# STM32F746ZGY7 register map
File version: 1.0
Registers are 32-bit, access not given, reset 0x0 unless marked. A register's access mark holds for its fields unless they carry their own. Offsets are from the block's base; [hi:lo] are bit positions; {n}, {i} and the like mark numbered series.

## ADC1
Base 0x40012000
Same registers: ADC3 0x40012200
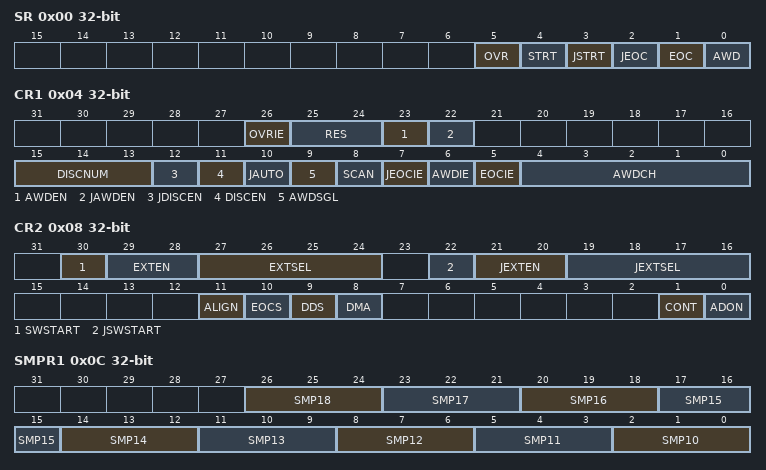
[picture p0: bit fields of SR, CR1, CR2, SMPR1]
0x00 SR
  [5] OVR, [4] STRT, [3] JSTRT, [2] JEOC, [1] EOC, [0] AWD
0x04 CR1
  [26] OVRIE, [25:24] RES, [23] AWDEN, [22] JAWDEN, [15:13] DISCNUM, [12] JDISCEN, [11] DISCEN, [10] JAUTO, [9] AWDSGL, [8] SCAN, [7] JEOCIE, [6] AWDIE, [5] EOCIE, [4:0] AWDCH
0x08 CR2
  [30] SWSTART, [29:28] EXTEN, [27:24] EXTSEL, [22] JSWSTART, [21:20] JEXTEN, [19:16] JEXTSEL, [11] ALIGN, [10] EOCS, [9] DDS, [8] DMA, [1] CONT, [0] ADON
0x0C SMPR1
  [3n-28:3n-30] SMP{n} (n=10..18)
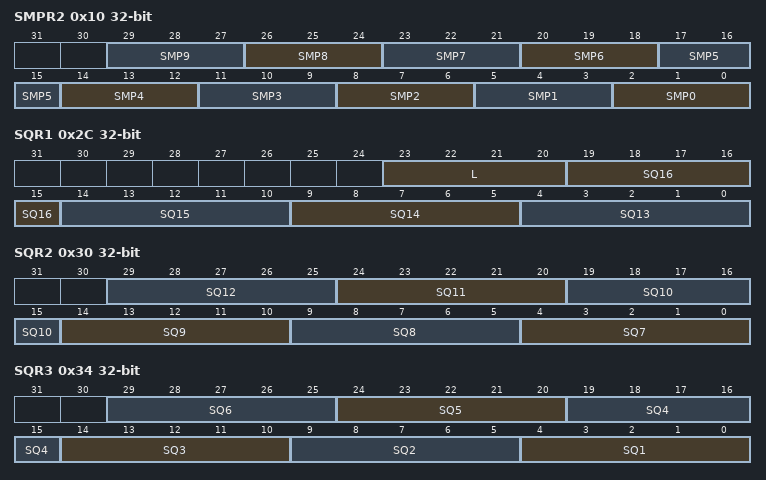
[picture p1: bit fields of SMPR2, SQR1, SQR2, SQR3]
0x10 SMPR2
  [3n+2:3n] SMP{n} (n=0..9)
{0x10+4i} JOFR{i} (i=1..4)
  [11:0] JOFFSET{i}
0x24 HTR
  [11:0] HT
0x28 LTR
  [11:0] LT
0x2C SQR1
  [23:20] L, [5n-61:5n-65] SQ{n} (n=13..16)
0x30 SQR2
  [5n-31:5n-35] SQ{n} (n=7..12)
0x34 SQR3
  [5n-1:5n-5] SQ{n} (n=1..6)
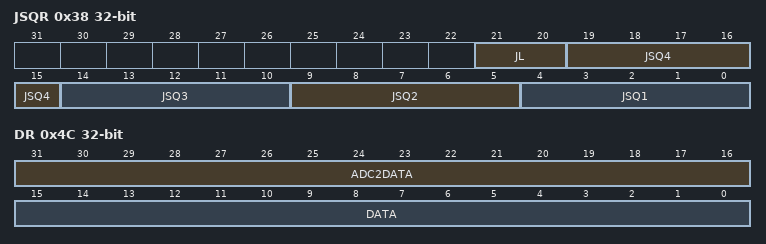
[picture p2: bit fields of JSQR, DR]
0x38 JSQR
  [21:20] JL, [5n-1:5n-5] JSQ{n} (n=1..4)
{0x38+4i} JDR{i} (i=1..4)
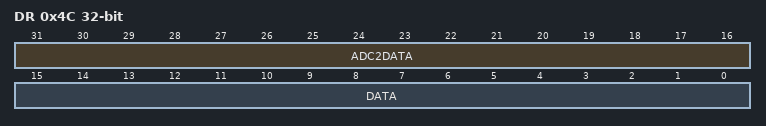
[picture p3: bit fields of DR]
0x4C DR
  [31:16] ADC2DATA, [15:0] DATA

## ADC2
Base 0x40012100
Registers as ADC1; these are added or differ:
0x4C DR
  [31:16] ADC2DATA, [15:0] DATA

## ADC
Base 0x40012300
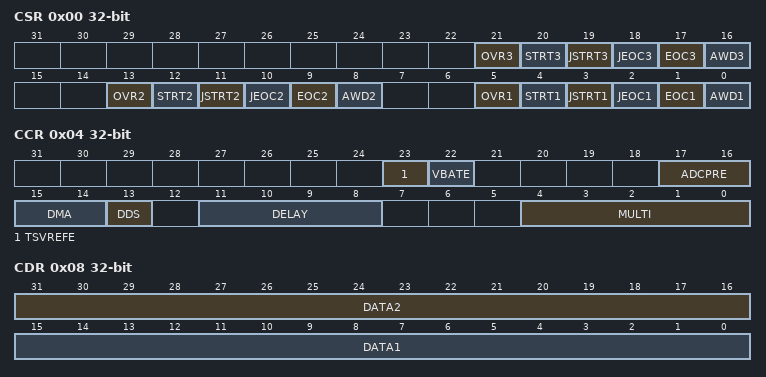
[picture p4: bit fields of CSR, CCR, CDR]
0x00 CSR
  [21] OVR3, [20] STRT3, [19] JSTRT3, [18] JEOC3, [17] EOC3, [16] AWD3, [13] OVR2, [12] STRT2, [11] JSTRT2, [10] JEOC2, [9] EOC2, [8] AWD2, [5] OVR1, [4] STRT1, [3] JSTRT1, [2] JEOC1, [1] EOC1, [0] AWD1
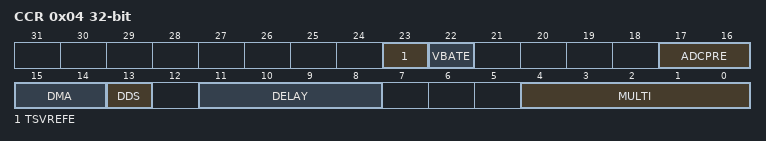
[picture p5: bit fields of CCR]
0x04 CCR
  [23] TSVREFE, [22] VBATE, [17:16] ADCPRE, [15:14] DMA, [13] DDS, [11:8] DELAY, [4:0] MULTI
0x08 CDR
  [31:16] DATA2, [15:0] DATA1

## ADC123_COMMON
Base 0x40012300
Registers as ADC; these are added or differ:
0x04 CCR
  [23] TSVREFE, [22] VBATE, [17:16] ADCPRE, [15:14] DMA, [13] DDS, [11:8] DELAY, [4:0] MULTI

## SDMMC1
Base 0x40012C00
0x00 POWER
  [1:0] PWRCTRL
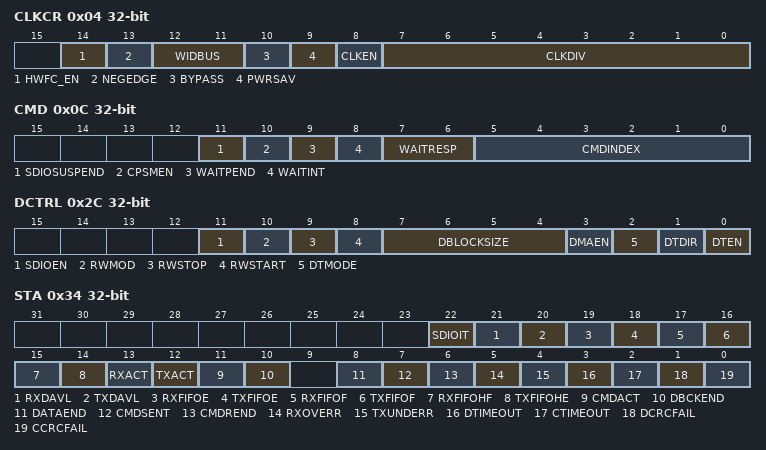
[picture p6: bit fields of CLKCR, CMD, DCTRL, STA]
0x04 CLKCR
  [14] HWFC_EN, [13] NEGEDGE, [12:11] WIDBUS, [10] BYPASS, [9] PWRSAV, [8] CLKEN, [7:0] CLKDIV
0x08 ARG
  [31:0] CMDARG
0x0C CMD
  [11] SDIOSUSPEND, [10] CPSMEN, [9] WAITPEND, [8] WAITINT, [7:6] WAITRESP, [5:0] CMDINDEX
0x10 RESPCMD
  [5:0] RESPCMD
{0x10+4i} RESP{i} (i=1..4)
  [31:0] CARDSTATUS{i}
0x24 DTIMER
  [31:0] DATATIME
0x28 DLEN
  [24:0] DATALENGTH
0x2C DCTRL
  [11] SDIOEN, [10] RWMOD, [9] RWSTOP, [8] RWSTART, [7:4] DBLOCKSIZE, [3] DMAEN, [2] DTMODE, [1] DTDIR, [0] DTEN
0x30 DCOUNT
  [24:0] DATACOUNT
0x34 STA
  [22] SDIOIT, [21] RXDAVL, [20] TXDAVL, [19] RXFIFOE, [18] TXFIFOE, [17] RXFIFOF, [16] TXFIFOF, [15] RXFIFOHF, [14] TXFIFOHE, [13] RXACT, [12] TXACT, [11] CMDACT, [10] DBCKEND, [8] DATAEND, [7] CMDSENT, [6] CMDREND, [5] RXOVERR, [4] TXUNDERR, [3] DTIMEOUT, [2] CTIMEOUT, [1] DCRCFAIL, [0] CCRCFAIL
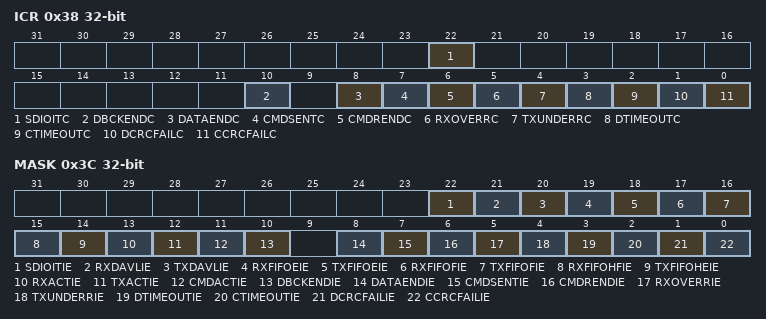
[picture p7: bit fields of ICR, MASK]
0x38 ICR
  [22] SDIOITC, [10] DBCKENDC, [8] DATAENDC, [7] CMDSENTC, [6] CMDRENDC, [5] RXOVERRC, [4] TXUNDERRC, [3] DTIMEOUTC, [2] CTIMEOUTC, [1] DCRCFAILC, [0] CCRCFAILC
0x3C MASK
  [22] SDIOITIE, [21] RXDAVLIE, [20] TXDAVLIE, [19] RXFIFOEIE, [18] TXFIFOEIE, [17] RXFIFOFIE, [16] TXFIFOFIE, [15] RXFIFOHFIE, [14] TXFIFOHEIE, [13] RXACTIE, [12] TXACTIE, [11] CMDACTIE, [10] DBCKENDIE, [8] DATAENDIE, [7] CMDSENTIE, [6] CMDRENDIE, [5] RXOVERRIE, [4] TXUNDERRIE, [3] DTIMEOUTIE, [2] CTIMEOUTIE, [1] DCRCFAILIE, [0] CCRCFAILIE
0x48 FIFOCNT
  [23:0] FIFOCOUNT
0x80 FIFO
  [31:0] FIFODATA

## SYSCFG
Base 0x40013800
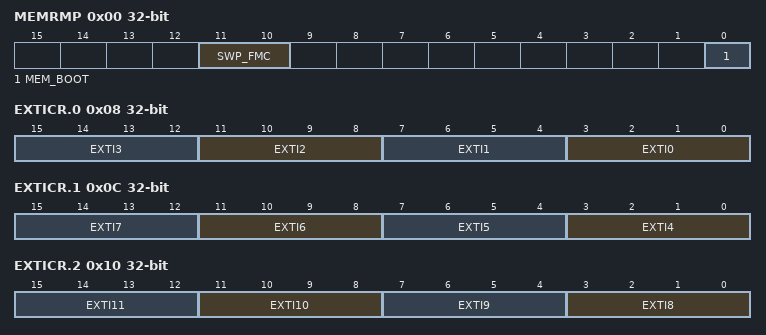
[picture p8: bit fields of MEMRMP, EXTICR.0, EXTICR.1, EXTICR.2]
0x00 MEMRMP
  [11:10] SWP_FMC, [0] MEM_BOOT
0x04 PMC
  [23] MII_RMII_SEL, [18] ADC3DC2, [17] ADC2DC2, [18:16] ADCxDC2, [n-2] I2C_PB{n}_FMP (n=6..9), [n-1] I2C{n}_FMP (n=1..4)
0x08 EXTICR.0
  [4n+3:4n] EXTI{n} (n=0..3)
0x0C EXTICR.1
  [4n-13:4n-16] EXTI{n} (n=4..7)
0x10 EXTICR.2
  [4n-29:4n-32] EXTI{n} (n=8..11)
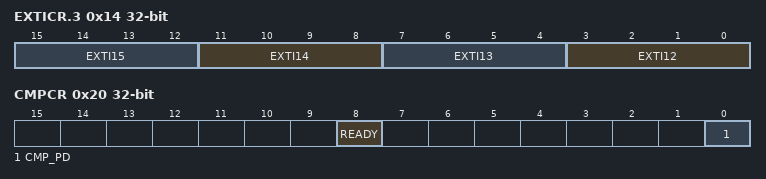
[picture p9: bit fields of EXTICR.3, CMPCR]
0x14 EXTICR.3
  [4n-45:4n-48] EXTI{n} (n=12..15)
0x20 CMPCR
  [8] READY, [0] CMP_PD

## EXTI
Base 0x40013C00
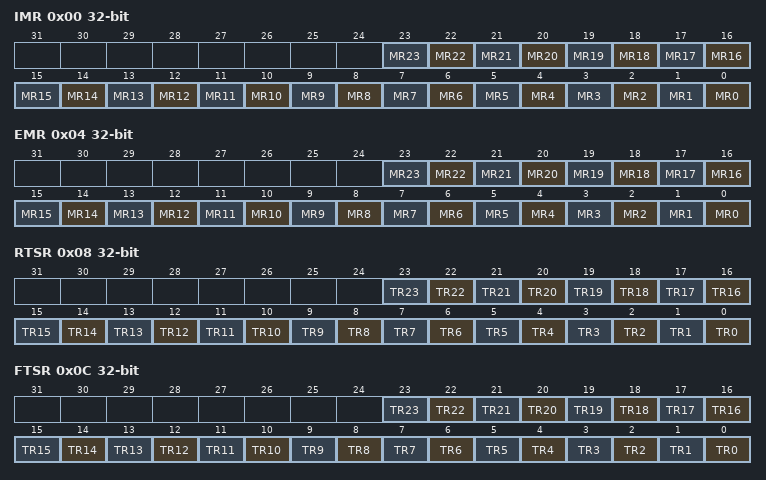
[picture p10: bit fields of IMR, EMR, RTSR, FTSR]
0x00 IMR
  [n] MR{n} (n=0..23)
0x04 EMR
  [n] MR{n} (n=0..23)
0x08 RTSR
  [n] TR{n} (n=0..23)
0x0C FTSR
  [n] TR{n} (n=0..23)
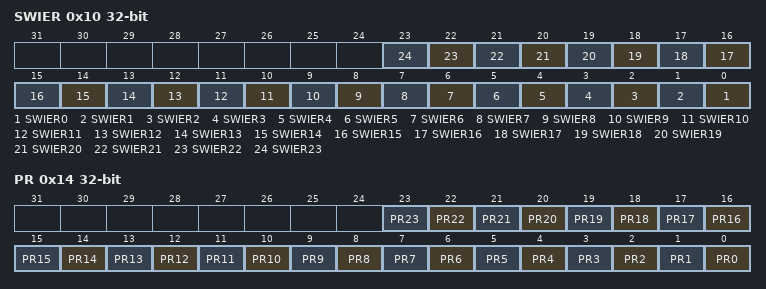
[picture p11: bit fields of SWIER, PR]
0x10 SWIER
  [n] SWIER{n} (n=0..23)
0x14 PR
  [n] PR{n} (n=0..23)
